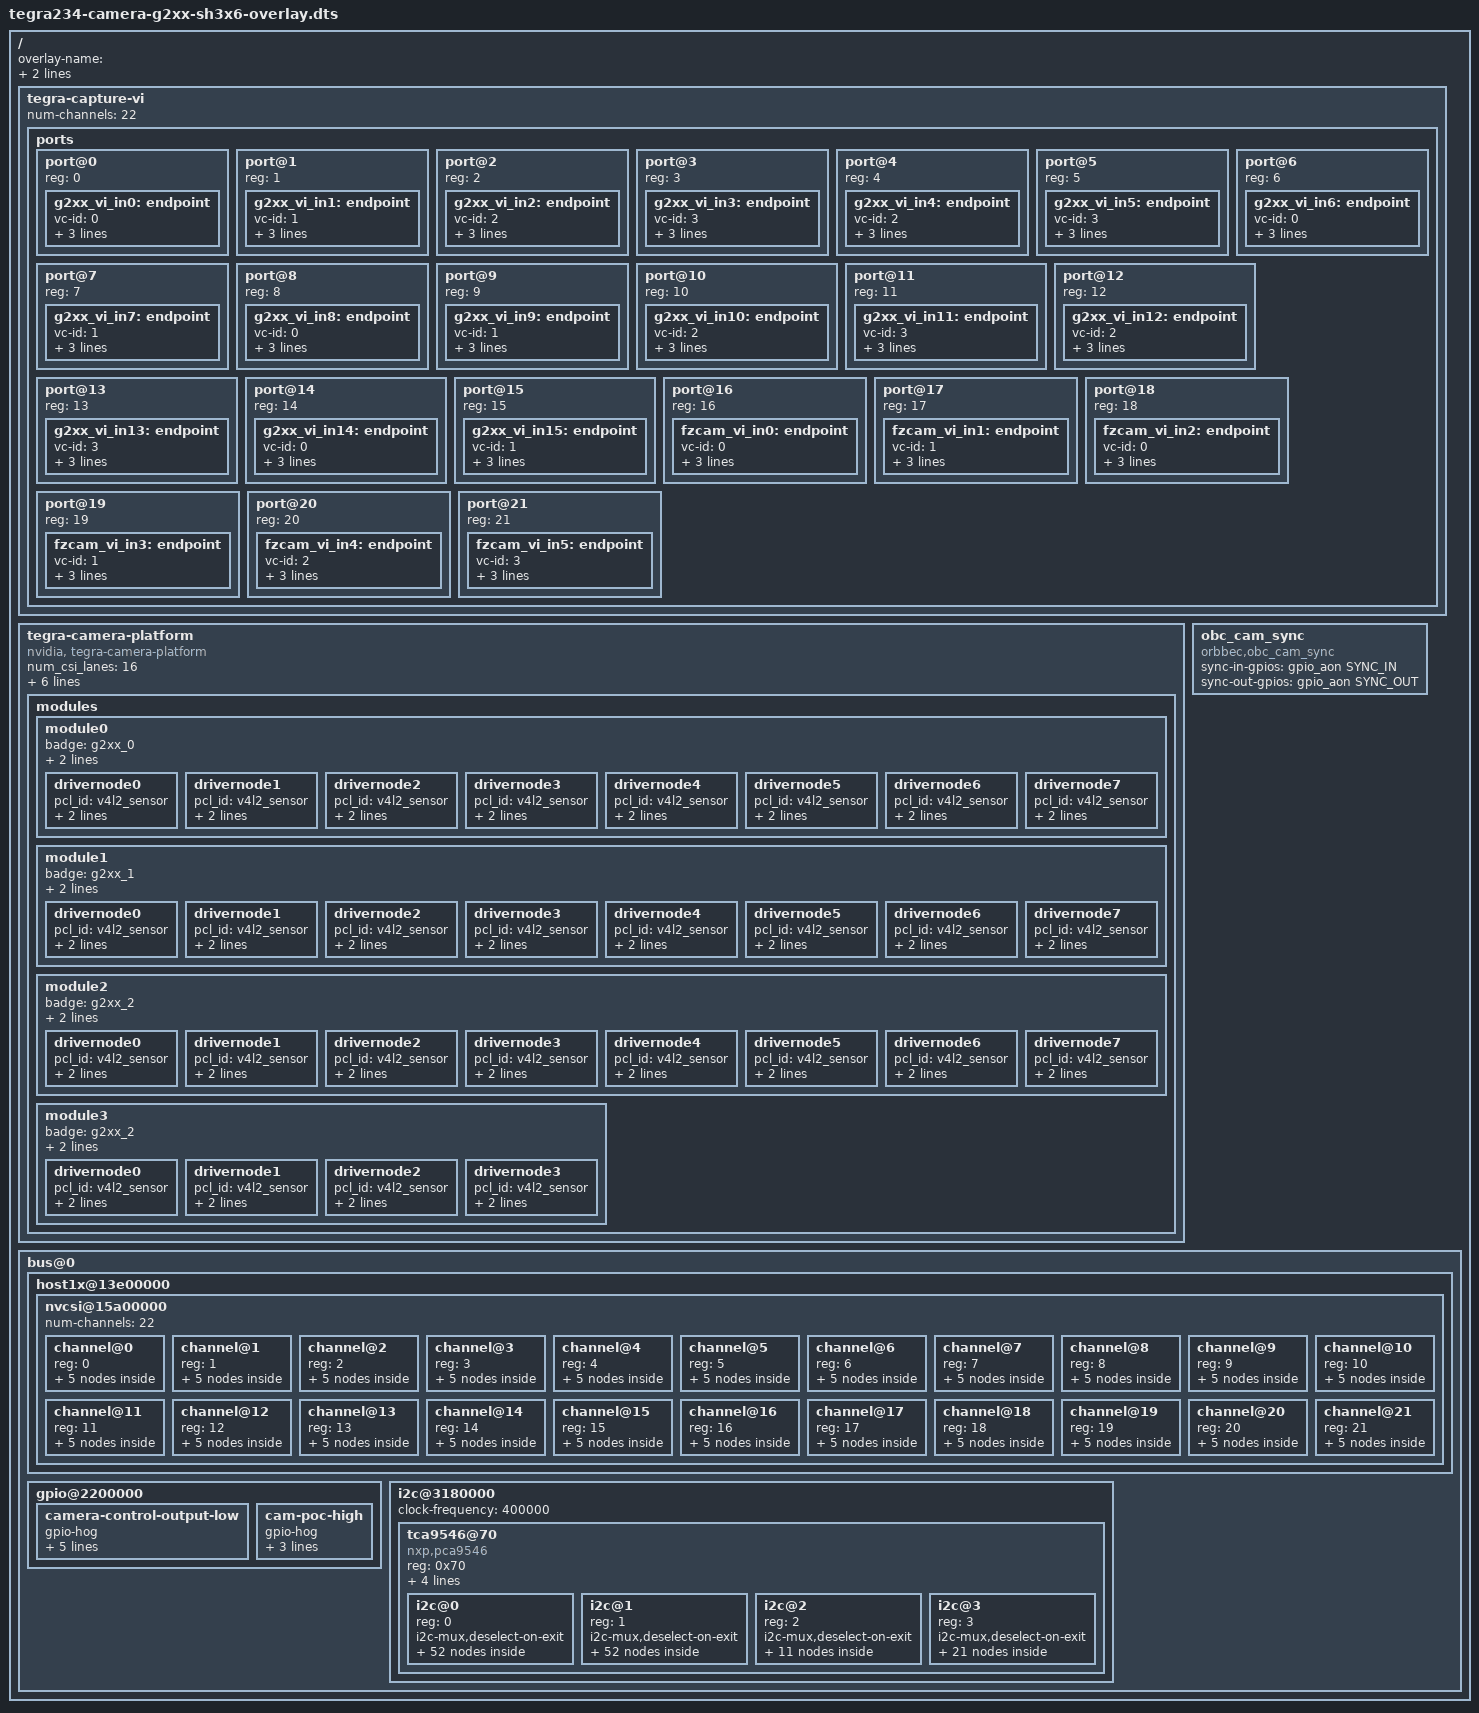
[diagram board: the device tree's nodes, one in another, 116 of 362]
// SPDX-License-Identifier: GPL-2.0-only
// SPDX-FileCopyrightText: Copyright (c) 2024-2024, ORBBEC CORPORATION.  All rights reserved.

/dts-v1/;
/plugin/;

#include <dt-bindings/clock/tegra234-clock.h>
#include <dt-bindings/gpio/tegra234-gpio.h>
#include <dt-bindings/tegra234-p3737-0000+p3701-0000.h>
#include <dt-bindings/pinctrl/pinctrl-tegra.h>

#define CAM1_PWDN	TEGRA234_MAIN_GPIO(H, 6)
#define CAM2_PWDN	TEGRA234_MAIN_GPIO(H, 3)
#define CAM3_PWDN	TEGRA234_MAIN_GPIO(AC, 0)
#define CAM4_PWDN	TEGRA234_MAIN_GPIO(AC, 1)

#define ISX031_POC	TEGRA234_MAIN_GPIO(AC, 4)
#define D457_POC	TEGRA234_MAIN_GPIO(AC, 7)

#define SYNC_OUT   TEGRA234_AON_GPIO(CC, 2)	//(CC, 2)
#define SYNC_IN    TEGRA234_AON_GPIO(BB, 0) //(BB, 0)
//#define SYNC_IN    TEGRA234_AON_GPIO(AA, 4) //(AA, 4)   // MAX3_CSI_SYNC

#define PPS_TRIGGER  TEGRA234_AON_GPIO(BB, 2)//(BB, 2)

#define CAMERA_I2C_MUX_BUS(x) (0x1E + x)

/* camera control gpio definitions */
/ {
	overlay-name = "Jetson Sensing Camera G335Lg And SH3 x6";
    jetson-header-name = "Jetson AGX CSI Connector";
    compatible = JETSON_COMPATIBLE;
	
	fragment@0 {
		target-path = "/";
		__overlay__ {
			tegra-capture-vi {
				num-channels = <22>;
				ports {
					status = "okay";
					#address-cells = <1>;
					#size-cells = <0>;
					port@0 {
						reg = <0>;
						status = "okay";
						g2xx_vi_in0: endpoint {
							status = "okay";
							vc-id = <0>;
							port-index = <4>; //0
							bus-width = <4>;
							remote-endpoint = <&g2xx_csi_out0>;
						};
					};
					port@1 {
						reg = <1>;
						status = "okay";
						g2xx_vi_in1: endpoint {
							status = "okay";
							vc-id = <1>;
							port-index = <4>; //0
							bus-width = <4>;
							remote-endpoint = <&g2xx_csi_out1>;
						};
					};
					port@2 {
						reg = <2>;
						status = "okay";
						g2xx_vi_in2: endpoint {
							status = "okay";
							vc-id = <2>;
							port-index = <4>; //0
							bus-width = <4>;
							remote-endpoint = <&g2xx_csi_out2>;
						};
					};
					port@3 {
						reg = <3>;
						status = "okay";
						g2xx_vi_in3: endpoint {
							status = "okay";
							vc-id = <3>;
							port-index = <4>; //0
							bus-width = <4>;
							remote-endpoint = <&g2xx_csi_out3>;
						};
					};

					port@4 {
						reg = <4>;
						status = "okay";
						g2xx_vi_in4: endpoint {
							status = "okay";
							vc-id = <2>;
							port-index = <4>; //1
							bus-width = <4>;
							remote-endpoint = <&g2xx_csi_out4>;
						};
					};
					port@5 {
						reg = <5>;
						status = "okay";
						g2xx_vi_in5: endpoint {
							status = "okay";
							vc-id = <3>;
							port-index = <4>; //1
							bus-width = <4>;
							remote-endpoint = <&g2xx_csi_out5>;
						};
					};
					port@6 {
						reg = <6>;
						status = "okay";
						g2xx_vi_in6: endpoint {
							status = "okay";
							vc-id = <0>;
							port-index = <4>; //1
							bus-width = <4>;
							remote-endpoint = <&g2xx_csi_out6>;
						};
					};
					port@7 {
						reg = <7>;
						status = "okay";
						g2xx_vi_in7: endpoint {
							status = "okay";
							vc-id = <1>;
							port-index = <4>; //1
							bus-width = <4>;
							remote-endpoint = <&g2xx_csi_out7>;
						};
					};

					port@8 {
						reg = <8>;
						status = "okay";
						g2xx_vi_in8: endpoint {
							status = "okay";
							vc-id = <0>;
							port-index = <2>; //2
							bus-width = <4>;
							remote-endpoint = <&g2xx_csi_out8>;
						};
					};
					port@9 {
						reg = <9>;
						status = "okay";
						g2xx_vi_in9: endpoint {
							status = "okay";
							vc-id = <1>;
							port-index = <2>; //2
							bus-width = <4>;
							remote-endpoint = <&g2xx_csi_out9>;
						};
					};
					port@10 {
						reg = <10>;
						status = "okay";
						g2xx_vi_in10: endpoint {
							status = "okay";
							vc-id = <2>;
							port-index = <2>; //2
							bus-width = <4>;
							remote-endpoint = <&g2xx_csi_out10>;
						};
					};
					port@11 {
						reg = <11>;
						status = "okay";
						g2xx_vi_in11: endpoint {
							status = "okay";
							vc-id = <3>;
							port-index = <2>; //2
							bus-width = <4>;
							remote-endpoint = <&g2xx_csi_out11>;
						};
					};

					port@12 {
						reg = <12>;
						status = "okay";
						g2xx_vi_in12: endpoint {
							status = "okay";
							vc-id = <2>;
							port-index = <2>; //3
							bus-width = <4>;
							remote-endpoint = <&g2xx_csi_out12>;
						};
					};
					port@13 {
						reg = <13>;
						status = "okay";
						g2xx_vi_in13: endpoint {
							status = "okay";
							vc-id = <3>;
							port-index = <2>; //3
							bus-width = <4>;
							remote-endpoint = <&g2xx_csi_out13>;
						};
					};
					port@14 {
						reg = <14>;
						status = "okay";
						g2xx_vi_in14: endpoint {
							status = "okay";
							vc-id = <0>;
							port-index = <2>; //3
							bus-width = <4>;
							remote-endpoint = <&g2xx_csi_out14>;
						};
					};
					port@15 {
						reg = <15>;
						status = "okay";
						g2xx_vi_in15: endpoint {
							status = "okay";
							vc-id = <1>;
							port-index = <2>; //3
							bus-width = <4>;
							remote-endpoint = <&g2xx_csi_out15>;
						};
					};
                    
                    //isx031
					port@16 {
						reg = <16>;
						status = "okay";
						fzcam_vi_in0: endpoint {
							status = "okay";
							vc-id = <0>;
							port-index = <0>; 
							bus-width = <4>;
							remote-endpoint = <&fzcam_csi_out0>;
						};
					};
					port@17 {
						reg = <17>;
						status = "okay";
						fzcam_vi_in1: endpoint {
							status = "okay";
							vc-id = <1>;
							port-index = <0>; 
							bus-width = <4>;
							remote-endpoint = <&fzcam_csi_out1>;
						};
					};
					
                    port@18 {
						reg = <18>;
						status = "okay";
						fzcam_vi_in2: endpoint {
							status = "okay";
							vc-id = <0>;
							port-index = <5>; //2
							bus-width = <4>;
							remote-endpoint = <&fzcam_csi_out2>;
						};
					};
					port@19 {
						reg = <19>;
						status = "okay";
						fzcam_vi_in3: endpoint {
							status = "okay";
							vc-id = <1>;
							port-index = <5>; //2
							bus-width = <4>;
							remote-endpoint = <&fzcam_csi_out3>;
						};
					};
					port@20 {
						reg = <20>;
						status = "okay";
						fzcam_vi_in4: endpoint {
							status = "okay";
							vc-id = <2>;
							port-index = <5>; 
							bus-width = <4>;
							remote-endpoint = <&fzcam_csi_out4>;
						};
					};
					port@21 {
						reg = <21>;
						status = "okay";
						fzcam_vi_in5: endpoint {
							status = "okay";
							vc-id = <3>;
							port-index = <5>; //3
							bus-width = <4>;
							remote-endpoint = <&fzcam_csi_out5>;
						};
					};
				};
			};
			tegra-camera-platform {
				compatible = "nvidia, tegra-camera-platform";

				num_csi_lanes = <16>;
				max_lane_speed = <4000000>;
				min_bits_per_pixel = <10>;
				vi_peak_byte_per_pixel = <2>;
				vi_bw_margin_pct = <25>;
				isp_peak_byte_per_pixel = <5>;
				isp_bw_margin_pct = <25>;

				modules {
					status = "okay";
					module0 {
						status = "okay";
						badge = "g2xx_0";
						position = "bottomleft";
						orientation = "1";
						drivernode0 {
							status = "okay";
							/* Declare PCL support driver (classically known as guid)  */
							pcl_id = "v4l2_sensor";
							/* Declare the device-tree hierarchy to driver instance */
							sysfs-device-tree = "/sys/firmware/devicetree/base/bus@0/i2c@3180000/tca9546@70/i2c@2/g2m0@66";
						};

						drivernode1 {
							status = "okay";
							/* Declare PCL support driver (classically known as guid)  */
							pcl_id = "v4l2_sensor";
							/* Declare the device-tree hierarchy to driver instance */
							sysfs-device-tree = "/sys/firmware/devicetree/base/bus@0/i2c@3180000/tca9546@70/i2c@2/g2m1@67";
						};

						drivernode2 {
							status = "okay";
							/* Declare PCL support driver (classically known as guid)  */
							pcl_id = "v4l2_sensor";
							/* Declare the device-tree hierarchy to driver instance */
							sysfs-device-tree = "/sys/firmware/devicetree/base/bus@0/i2c@3180000/tca9546@70/i2c@2/g2m2@68";
						};

						drivernode3 {
							status = "okay";
							/* Declare PCL support driver (classically known as guid)  */
							pcl_id = "v4l2_sensor";
							/* Declare the device-tree hierarchy to driver instance */
							sysfs-device-tree = "/sys/firmware/devicetree/base/bus@0/i2c@3180000/tca9546@70/i2c@0/g2m3@69";
						};

						drivernode4 {
							status = "okay";
							/* Declare PCL support driver (classically known as guid)  */
							pcl_id = "v4l2_sensor";
							/* Declare the device-tree hierarchy to driver instance */
							sysfs-device-tree = "/sys/firmware/devicetree/base/bus@0/i2c@3180000/tca9546@70/i2c@0/g2m0@6A";
						};

						drivernode5 {
							status = "okay";
							/* Declare PCL support driver (classically known as guid)  */
							pcl_id = "v4l2_sensor";
							/* Declare the device-tree hierarchy to driver instance */
							sysfs-device-tree = "/sys/firmware/devicetree/base/bus@0/i2c@3180000/tca9546@70/i2c@0/g2m1@6B";
						};

						drivernode6 {
							status = "okay";
							/* Declare PCL support driver (classically known as guid)  */
							pcl_id = "v4l2_sensor";
							/* Declare the device-tree hierarchy to driver instance */
							sysfs-device-tree = "/sys/firmware/devicetree/base/bus@0/i2c@3180000/tca9546@70/i2c@0/g2m2@6C";
						};

						drivernode7 {
							status = "okay";
							/* Declare PCL support driver (classically known as guid)  */
							pcl_id = "v4l2_sensor";
							/* Declare the device-tree hierarchy to driver instance */
							sysfs-device-tree = "/sys/firmware/devicetree/base/bus@0/i2c@3180000/tca9546@70/i2c@0/g2m3@6D";
						};
					};

					module1 {
						status = "okay";
						badge = "g2xx_1";
						position = "bottomright";
						orientation = "1";

						drivernode0 {
							status = "okay";
							/* Declare PCL support driver (classically known as guid)  */
							pcl_id = "v4l2_sensor";
							sysfs-device-tree = "/sys/firmware/devicetree/base/bus@0/i2c@3180000/tca9546@70/i2c@1/g2m0@66";
						};

						drivernode1 {
							status = "okay";
							/* Declare PCL support driver (classically known as guid)  */
							pcl_id = "v4l2_sensor";
							/* Declare the device-tree hierarchy to driver instance */
							sysfs-device-tree = "/sys/firmware/devicetree/base/bus@0/i2c@3180000/tca9546@70/i2c@1/g2m1@67";
						};

						drivernode2 {
							status = "okay";
							/* Declare PCL support driver (classically known as guid)  */
							pcl_id = "v4l2_sensor";
							/* Declare the device-tree hierarchy to driver instance */
							sysfs-device-tree = "/sys/firmware/devicetree/base/bus@0/i2c@3180000/tca9546@70/i2c@1/g2m2@68";
						};

						drivernode3 {
							status = "okay";
							/* Declare PCL support driver (classically known as guid)  */
							pcl_id = "v4l2_sensor";
							/* Declare the device-tree hierarchy to driver instance */
							sysfs-device-tree = "/sys/firmware/devicetree/base/bus@0/i2c@3180000/tca9546@70/i2c@1/g2m3@69";
						};

						drivernode4 {
							status = "okay";
								/* Declare PCL support driver (classically known as guid)  */
							pcl_id = "v4l2_sensor";
							/* Declare the device-tree hierarchy to driver instance */
							sysfs-device-tree = "/sys/firmware/devicetree/base/bus@0/i2c@3180000/tca9546@70/i2c@1/g2m0@6A";
						};

						drivernode5 {
							status = "okay";
							/* Declare PCL support driver (classically known as guid)  */
							pcl_id = "v4l2_sensor";
							/* Declare the device-tree hierarchy to driver instance */
							sysfs-device-tree = "/sys/firmware/devicetree/base/bus@0/i2c@3180000/tca9546@70/i2c@1/g2m1@6B";
						};

						drivernode6 {
							status = "okay";
							/* Declare PCL support driver (classically known as guid)  */
							pcl_id = "v4l2_sensor";
							/* Declare the device-tree hierarchy to driver instance */
							sysfs-device-tree = "/sys/firmware/devicetree/base/bus@0/i2c@3180000/tca9546@70/i2c@1/g2m2@6C";
						};

						drivernode7 {
							status = "okay";
							/* Declare PCL support driver (classically known as guid)  */
							pcl_id = "v4l2_sensor";
							/* Declare the device-tree hierarchy to driver instance */
							sysfs-device-tree = "/sys/firmware/devicetree/base/bus@0/i2c@3180000/tca9546@70/i2c@1/g2m3@6D";
						};
					};

					module2 {
						status = "okay";
						badge = "g2xx_2";
						position = "centerleft";
						orientation = "1";

						drivernode0 {
							status = "okay";
							/* Declare PCL support driver (classically known as guid)  */
							pcl_id = "v4l2_sensor";
							sysfs-device-tree = "/sys/firmware/devicetree/base/bus@0/i2c@3180000/tca9546@70/i2c@0/g2m0@66";
						};

						drivernode1 {
							status = "okay";
							/* Declare PCL support driver (classically known as guid)  */
							pcl_id = "v4l2_sensor";
							/* Declare the device-tree hierarchy to driver instance */
							sysfs-device-tree = "/sys/firmware/devicetree/base/bus@0/i2c@3180000/tca9546@70/i2c@0/g2m1@67";
						};

						drivernode2 {
							status = "okay";
							/* Declare PCL support driver (classically known as guid)  */
							pcl_id = "v4l2_sensor";
							/* Declare the device-tree hierarchy to driver instance */
							sysfs-device-tree = "/sys/firmware/devicetree/base/bus@0/i2c@3180000/tca9546@70/i2c@0/g2m2@68";
						};

						drivernode3 {
							status = "okay";
							/* Declare PCL support driver (classically known as guid)  */
							pcl_id = "v4l2_sensor";
							/* Declare the device-tree hierarchy to driver instance */
							sysfs-device-tree = "/sys/firmware/devicetree/base/bus@0/i2c@3180000/tca9546@70/i2c@0/g2m3@69";
						};

						drivernode4 {
							status = "okay";
								/* Declare PCL support driver (classically known as guid)  */
							pcl_id = "v4l2_sensor";
							/* Declare the device-tree hierarchy to driver instance */
							sysfs-device-tree = "/sys/firmware/devicetree/base/bus@0/i2c@3180000/tca9546@70/i2c@0/g2m0@6A";
						};

						drivernode5 {
							status = "okay";
							/* Declare PCL support driver (classically known as guid)  */
							pcl_id = "v4l2_sensor";
							/* Declare the device-tree hierarchy to driver instance */
							sysfs-device-tree = "/sys/firmware/devicetree/base/bus@0/i2c@3180000/tca9546@70/i2c@0/g2m1@6B";
						};

						drivernode6 {
							status = "okay";
							/* Declare PCL support driver (classically known as guid)  */
							pcl_id = "v4l2_sensor";
							/* Declare the device-tree hierarchy to driver instance */
							sysfs-device-tree = "/sys/firmware/devicetree/base/bus@0/i2c@3180000/tca9546@70/i2c@0/g2m2@6C";
						};

						drivernode7 {
							status = "okay";
							/* Declare PCL support driver (classically known as guid)  */
							pcl_id = "v4l2_sensor";
							/* Declare the device-tree hierarchy to driver instance */
							sysfs-device-tree = "/sys/firmware/devicetree/base/bus@0/i2c@3180000/tca9546@70/i2c@0/g2m3@6D";
						};
					};
                    module3 {
						status = "okay";
						badge = "g2xx_2";
						position = "centerright";
						orientation = "1";

						drivernode0 {
							status = "okay";
							/* Declare PCL support driver (classically known as guid)  */
							pcl_id = "v4l2_sensor";
							sysfs-device-tree = "/sys/firmware/devicetree/base/bus@0/i2c@3180000/tca9546@70/i2c@3/g2m0@66";
						};

						drivernode1 {
							status = "okay";
							/* Declare PCL support driver (classically known as guid)  */
							pcl_id = "v4l2_sensor";
							/* Declare the device-tree hierarchy to driver instance */
							sysfs-device-tree = "/sys/firmware/devicetree/base/bus@0/i2c@3180000/tca9546@70/i2c@3/g2m1@67";
						};

						drivernode2 {
							status = "okay";
							/* Declare PCL support driver (classically known as guid)  */
							pcl_id = "v4l2_sensor";
							/* Declare the device-tree hierarchy to driver instance */
							sysfs-device-tree = "/sys/firmware/devicetree/base/bus@0/i2c@3180000/tca9546@70/i2c@3/g2m2@68";
						};

						drivernode3 {
							status = "okay";
							/* Declare PCL support driver (classically known as guid)  */
							pcl_id = "v4l2_sensor";
							/* Declare the device-tree hierarchy to driver instance */
							sysfs-device-tree = "/sys/firmware/devicetree/base/bus@0/i2c@3180000/tca9546@70/i2c@3/g2m3@69";
						};
					};
				};
			};

			obc_cam_sync {
				compatible = "orbbec,obc_cam_sync";
				sync-in-gpios = <&gpio_aon SYNC_IN GPIO_ACTIVE_HIGH>;
				sync-out-gpios = <&gpio_aon SYNC_OUT GPIO_ACTIVE_HIGH>;  //Use hrtimer to generate trigger signals
			};

			bus@0 {
				host1x@13e00000 {
					nvcsi@15a00000 {
						#address-cells = <1>;
						#size-cells = <0>;

						num-channels = <22>;

						channel@0 {
							reg = <0>;
							status = "okay";
							ports {
								status = "okay";
								#address-cells = <1>;
								#size-cells = <0>;
								port@0 {
									reg = <0>;
									status = "okay";
									g2xx_csi_in0: endpoint@0 {
										status = "okay";
										port-index = <4>; //0
										bus-width = <4>;
										remote-endpoint = <&g2m0_0_out>;
									};
								};
								port@1 {
									reg = <1>;
									status = "okay";
									g2xx_csi_out0: endpoint@1 {
										status = "okay";
										remote-endpoint = <&g2xx_vi_in0>;
									};
								};
							};
						};
						channel@1 {
							reg = <1>;
							status = "okay";
							ports {
								status = "okay";
								#address-cells = <1>;
								#size-cells = <0>;
								port@0 {
									reg = <0>;
									status = "okay";
									g2xx_csi_in1: endpoint@2 {
										status = "okay";
										port-index = <4>; //0
										bus-width = <4>;
										remote-endpoint = <&g2m0_1_out>;
									};
								};
								port@1 {
									reg = <1>;
									status = "okay";
									g2xx_csi_out1: endpoint@3 {
										status = "okay";
										remote-endpoint = <&g2xx_vi_in1>;
									};
								};
							};
						};
						channel@2 {
							reg = <2>;
							status = "okay";
							ports {
								status = "okay";
								#address-cells = <1>;
								#size-cells = <0>;
								port@0 {
									reg = <0>;
									status = "okay";
									g2xx_csi_in2: endpoint@4 {
										status = "okay";
										port-index = <4>; //0
										bus-width = <4>;
										remote-endpoint = <&g2m0_2_out>;
									};
								};
								port@1 {
									reg = <1>;
									status = "okay";
									g2xx_csi_out2: endpoint@5 {
										status = "okay";
										remote-endpoint = <&g2xx_vi_in2>;
									};
								};
							};
						};
						channel@3 {
							reg = <3>;
							status = "okay";
							ports {
								status = "okay";
								#address-cells = <1>;
								#size-cells = <0>;
								port@0 {
									reg = <0>;
									status = "okay";
									g2xx_csi_in3: endpoint@6 {
										status = "okay";
										port-index = <4>; //0
										bus-width = <4>;
										remote-endpoint = <&g2m0_3_out>;
									};
								};
								port@1 {
									reg = <1>;
									status = "okay";
									g2xx_csi_out3: endpoint@7 {
										status = "okay";
										remote-endpoint = <&g2xx_vi_in3>;
									};
								};
							};
						};

						channel@4 {
							reg = <4>;
							status = "okay";
							ports {
								status = "okay";
								#address-cells = <1>;
								#size-cells = <0>;
								port@0 {
									reg = <0>;
									status = "okay";
									g2xx_csi_in4: endpoint@8 {
										status = "okay";
										port-index = <4>; //1
										bus-width = <4>;
										remote-endpoint = <&g2m1_0_out>;
									};
								};
								port@1 {
									reg = <1>;
									status = "okay";
									g2xx_csi_out4: endpoint@9 {
										status = "okay";
										remote-endpoint = <&g2xx_vi_in4>;
									};
								};
							};
						};
						channel@5 {
							reg = <5>;
							status = "okay";
							ports {
								status = "okay";
								#address-cells = <1>;
								#size-cells = <0>;
								port@0 {
									reg = <0>;
									status = "okay";
									g2xx_csi_in5: endpoint@10 {
										status = "okay";
										port-index = <4>; //1
										bus-width = <4>;
										remote-endpoint = <&g2m1_1_out>;
									};
								};
								port@1 {
									reg = <1>;
									status = "okay";
									g2xx_csi_out5: endpoint@11 {
										status = "okay";
										remote-endpoint = <&g2xx_vi_in5>;
									};
								};
							};
						};
						channel@6 {
							reg = <6>;
							status = "okay";
							ports {
								status = "okay";
								#address-cells = <1>;
								#size-cells = <0>;
								port@0 {
									reg = <0>;
									status = "okay";
									g2xx_csi_in6: endpoint@12 {
										status = "okay";
										port-index = <4>; //1
										bus-width = <4>;
										remote-endpoint = <&g2m1_2_out>;
									};
								};
								port@1 {
									reg = <1>;
									status = "okay";
									g2xx_csi_out6: endpoint@13 {
										status = "okay";
										remote-endpoint = <&g2xx_vi_in6>;
									};
								};
							};
						};
						channel@7 {
							reg = <7>;
							status = "okay";
							ports {
								status = "okay";
								#address-cells = <1>;
								#size-cells = <0>;
								port@0 {
									reg = <0>;
									status = "okay";
									g2xx_csi_in7: endpoint@14 {
										status = "okay";
										port-index = <4>; //1
										bus-width = <4>;
										remote-endpoint = <&g2m1_3_out>;
									};
								};
								port@1 {
									reg = <1>;
									status = "okay";
									g2xx_csi_out7: endpoint@15 {
										status = "okay";
										remote-endpoint = <&g2xx_vi_in7>;
									};
								};
							};
						};

						channel@8 {
							reg = <8>;
							status = "okay";
							ports {
								status = "okay";
								#address-cells = <1>;
								#size-cells = <0>;
								port@0 {
									reg = <0>;
									status = "okay";
									g2xx_csi_in8: endpoint@16 {
										status = "okay";
										port-index = <2>; //2
										bus-width = <4>;
										remote-endpoint = <&g2m2_0_out>;
									};
								};
								port@1 {
									reg = <1>;
									status = "okay";
									g2xx_csi_out8: endpoint@17 {
										status = "okay";
										remote-endpoint = <&g2xx_vi_in8>;
									};
								};
							};
						};
						channel@9 {
							reg = <9>;
							status = "okay";
							ports {
								status = "okay";
								#address-cells = <1>;
								#size-cells = <0>;
								port@0 {
									reg = <0>;
									status = "okay";
									g2xx_csi_in9: endpoint@18 {
										status = "okay";
										port-index = <2>; //2
										bus-width = <4>;
										remote-endpoint = <&g2m2_1_out>;
									};
								};
								port@1 {
									reg = <1>;
									status = "okay";
									g2xx_csi_out9: endpoint@19 {
										status = "okay";
										remote-endpoint = <&g2xx_vi_in9>;
									};
								};
							};
						};
						channel@10 {
							reg = <10>;
							status = "okay";
							ports {
								status = "okay";
								#address-cells = <1>;
								#size-cells = <0>;
								port@0 {
									reg = <0>;
									status = "okay";
									g2xx_csi_in10: endpoint@20 {
										status = "okay";
										port-index = <2>; //2
										bus-width = <4>;
										remote-endpoint = <&g2m2_2_out>;
									};
								};
								port@1 {
									reg = <1>;
									status = "okay";
									g2xx_csi_out10: endpoint@21 {
										status = "okay";
										remote-endpoint = <&g2xx_vi_in10>;
									};
								};
							};
						};
						channel@11 {
							reg = <11>;
							status = "okay";
							ports {
								status = "okay";
								#address-cells = <1>;
								#size-cells = <0>;
								port@0 {
									reg = <0>;
									status = "okay";
									g2xx_csi_in11: endpoint@22 {
										status = "okay";
										port-index = <2>; //2
										bus-width = <4>;
										remote-endpoint = <&g2m2_3_out>;
									};
								};
								port@1 {
									reg = <1>;
									status = "okay";
									g2xx_csi_out11: endpoint@23 {
										status = "okay";
										remote-endpoint = <&g2xx_vi_in11>;
									};
								};
							};
						};

						channel@12 {
							reg = <12>;
							status = "okay";
							ports {
								status = "okay";
								#address-cells = <1>;
								#size-cells = <0>;
								port@0 {
									reg = <0>;
									status = "okay";
									g2xx_csi_in12: endpoint@24 {
										status = "okay";
										port-index = <2>; //3
										bus-width = <4>;
										remote-endpoint = <&g2m3_0_out>;
									};
								};
								port@1 {
									reg = <1>;
									status = "okay";
									g2xx_csi_out12: endpoint@25 {
										status = "okay";
										remote-endpoint = <&g2xx_vi_in12>;
									};
								};
							};
						};
						channel@13 {
							reg = <13>;
							status = "okay";
							ports {
								status = "okay";
								#address-cells = <1>;
								#size-cells = <0>;
								port@0 {
									reg = <0>;
									status = "okay";
									g2xx_csi_in13: endpoint@26 {
										status = "okay";
										port-index = <2>; //3
										bus-width = <4>;
										remote-endpoint = <&g2m3_1_out>;
									};
								};
								port@1 {
									reg = <1>;
									status = "okay";
									g2xx_csi_out13: endpoint@27 {
										status = "okay";
										remote-endpoint = <&g2xx_vi_in13>;
									};
								};
							};
						};
						channel@14 {
							reg = <14>;
							status = "okay";
							ports {
								status = "okay";
								#address-cells = <1>;
								#size-cells = <0>;
								port@0 {
									reg = <0>;
									status = "okay";
									g2xx_csi_in14: endpoint@28 {
										status = "okay";
										port-index = <2>; //3
										bus-width = <4>;
										remote-endpoint = <&g2m3_2_out>;
									};
								};
								port@1 {
									reg = <1>;
									status = "okay";
									g2xx_csi_out14: endpoint@29 {
										status = "okay";
										remote-endpoint = <&g2xx_vi_in14>;
									};
								};
							};
						};
						channel@15 {
							reg = <15>;
							status = "okay";
							ports {
								status = "okay";
								#address-cells = <1>;
								#size-cells = <0>;
								port@0 {
									reg = <0>;
									status = "okay";
									g2xx_csi_in15: endpoint@30 {
										status = "okay";
										port-index = <2>; //3
										bus-width = <4>;
										remote-endpoint = <&g2m3_3_out>;
									};
								};
								port@1 {
									reg = <1>;
									status = "okay";
									g2xx_csi_out15: endpoint@31 {
										status = "okay";
										remote-endpoint = <&g2xx_vi_in15>;
									};
								};
							};
						};

                        //isx031
						channel@16 {
							reg = <16>;
							status = "okay";
							ports {
								status = "okay";
								#address-cells = <1>;
								#size-cells = <0>;
								port@0 {
									reg = <0>;
									status = "okay";
									fzcam_csi_in0: endpoint@32 {
										status = "okay";
										port-index = <0>; 
										bus-width = <4>;
										remote-endpoint = <&fzcam_fzcam_out0>;
									};
								};
								port@1 {
									reg = <1>;
									status = "okay";
									fzcam_csi_out0: endpoint@33 {
										status = "okay";
										remote-endpoint = <&fzcam_vi_in0>;
									};
								};
							};
						};
						channel@17 {
							reg = <17>;
							status = "okay";
							ports {
								status = "okay";
								#address-cells = <1>;
								#size-cells = <0>;
								port@0 {
									reg = <0>;
									status = "okay";
									fzcam_csi_in1: endpoint@34 {
										status = "okay";
										port-index = <0>; 
										bus-width = <4>;
										remote-endpoint = <&fzcam_fzcam_out1>;
									};
								};
								port@1 {
									reg = <1>;
									status = "okay";
									fzcam_csi_out1: endpoint@35 {
										status = "okay";
										remote-endpoint = <&fzcam_vi_in1>;
									};
								};
							};
						};
                        
						channel@18 {
							reg = <18>;
							status = "okay";
							ports {
								status = "okay";
								#address-cells = <1>;
								#size-cells = <0>;
								port@0 {
									reg = <0>;
									status = "okay";
									fzcam_csi_in2: endpoint@36 {
										status = "okay";
										port-index = <6>; 
										bus-width = <4>;
										remote-endpoint = <&fzcam_fzcam_out2>;
									};
								};
								port@1 {
									reg = <1>;
									status = "okay";
									fzcam_csi_out2: endpoint@37 {
										status = "okay";
										remote-endpoint = <&fzcam_vi_in2>;
									};
								};
							};
						};
						channel@19 {
							reg = <19>;
							status = "okay";
							ports {
								status = "okay";
								#address-cells = <1>;
								#size-cells = <0>;
								port@0 {
									reg = <0>;
									status = "okay";
									fzcam_csi_in3: endpoint@38 {
										status = "okay";
										port-index = <6>; 
										bus-width = <4>;
										remote-endpoint = <&fzcam_fzcam_out3>;
									};
								};
								port@1 {
									reg = <1>;
									status = "okay";
									fzcam_csi_out3: endpoint@39 {
										status = "okay";
										remote-endpoint = <&fzcam_vi_in3>;
									};
								};
							};
						};
						channel@20 {
							reg = <20>;
							status = "okay";
							ports {
								status = "okay";
								#address-cells = <1>;
								#size-cells = <0>;
								port@0 {
									reg = <0>;
									status = "okay";
									fzcam_csi_in4: endpoint@40 {
										status = "okay";
										port-index = <6>; 
										bus-width = <4>;
										remote-endpoint = <&fzcam_fzcam_out4>;
									};
								};
								port@1 {
									reg = <1>;
									status = "okay";
									fzcam_csi_out4: endpoint@41 {
										status = "okay";
										remote-endpoint = <&fzcam_vi_in4>;
									};
								};
							};
						};
						channel@21 {
							reg = <21>;
							status = "okay";
							ports {
								status = "okay";
								#address-cells = <1>;
								#size-cells = <0>;
								port@0 {
									reg = <0>;
									status = "okay";
									fzcam_csi_in5: endpoint@42 {
										status = "okay";
										port-index = <6>; 
										bus-width = <4>;
										remote-endpoint = <&fzcam_fzcam_out5>;
									};
								};
								port@1 {
									reg = <1>;
									status = "okay";
									fzcam_csi_out5: endpoint@43 {
										status = "okay";
										remote-endpoint = <&fzcam_vi_in5>;
									};
								};
							};
						};
					};
				};

				gpio@2200000 {
					// cam-pwdn-high {
					// 	gpio-hog;
					// 	output-high;
					// 	gpios = <CAM1_PWDN 0 CAM2_PWDN 0
					// 		 CAM3_PWDN 0 CAM4_PWDN 0>;
					// 	// gpios = <CAM1_PWDN 0 CAM2_PWDN 0>;
					// 	label = "cam1-pwdn", "cam2-pwdn",
					// 		"cam3-pwdn", "cam4-pwdn";
					// 	// label = "cam1-pwdn", "cam2-pwdn";
					// };

                    
					camera-control-output-low {
						gpio-hog;
						output-low;
						gpios = <CAM1_PWDN 0 CAM2_PWDN 0
						    CAM3_PWDN 0 CAM4_PWDN 0>;
						label = "cam1-pwdn", "cam2-pwdn",
						    "cam3-pwdn", "cam4-pwdn";
					};
				    

					cam-poc-high {
						gpio-hog;
						output-high;
						gpios = <ISX031_POC 0 D457_POC 0>;
						label = "isx031-poc", "d457-poc";
					};
					// camera-control-output-high {
					// 	gpio-hog;
					// 	output-high;
					// 	gpios = <ISX031_POC 0 D457_POC 0>; 
					// 	label = "isx031-poc", "d457-poc";
					// };
				};

				i2c@3180000 {
					status = "okay";
					clock-frequency = <400000>;
					tca9546@70 {
						status = "okay";
						reg = <0x70>;
						compatible = "nxp,pca9546";
						#address-cells = <1>;
						#size-cells = <0>;
						skip_mux_detect = "yes";
						vcc-supply = <&vdd_1v8_ls>;
						/*vcc-pullup-supply = <&battery_reg>;*/
						force_bus_start = <CAMERA_I2C_MUX_BUS(0)>;
						vcc_lp = "vcc";

						i2c@0 {
							status = "okay";
							reg = <0>; // line 4 of the I2C switch
							i2c-mux,deselect-on-exit;
							#address-cells = <1>;
							#size-cells = <0>;

                            g2m1_3: g2m3@6D {
								status = "okay";
								def-addr = <0x66>;
								reg = <0x6D>;
								compatible = "orbbec,g2xx";
								use_sensor_mode_id = "true";
								vcc-supply = <&vdd_1v8_ls>;
								cam-type = "IR_R";
								orbbec_cam_num = <1>;
								nvidia,gmsl-ser-device = <&ser0_b>;
								nvidia,gmsl-dser-device = <&dser0>;
								pps-gpios = <&gpio_aon PPS_TRIGGER GPIO_ACTIVE_LOW>;
								ports {
									#address-cells = <1>;
									#size-cells = <0>;

									port@0 {
										reg = <0>;
										g2m1_3_out: endpoint {
											vc-id = <1>;
											port-index = <4>;
											bus-width = <4>;
											remote-endpoint = <&g2xx_csi_in7>;
										};
									};
								};
								mode0 {
									pixel_t = "grey_y8";
									num_lanes = "4";
									csi_pixel_bit_depth = "8";
									active_w = "1280";
									active_h = "720";
									tegra_sinterface = "serial_e";
									mclk_khz = "24000";
									pix_clk_hz = "750000000";
									serdes_pix_clk_hz = "750000000";
									discontinuous_clk = "no";
									dpcm_enable = "false";
									cil_settletime = "0";
									line_length = "1280";
									mclk_multiplier = "15.625";
									embedded_metadata_height = "1";
									vc_id = "1";
								};
								gmsl-link {
									src-csi-port = "b"; //a = depth + ir_l, b = rgb + ir_r
									dst-csi-port = "a";
									serdes-csi-link = "b";
									csi-mode = "1x4";
									st-vc = <3>;
									vc-id = <1>;
									num-lanes = <4>;
								};
							};
							g2m1_2: g2m2@6C {
								status = "okay";
								def-addr = <0x66>;
								reg = <0x6C>;
								compatible = "orbbec,g2xx";
								use_sensor_mode_id = "true";
								vcc-supply = <&vdd_1v8_ls>;
								cam-type = "IR_L";
								orbbec_cam_num = <1>;
								nvidia,gmsl-ser-device = <&ser0_b>;
								nvidia,gmsl-dser-device = <&dser0>;
								pps-gpios = <&gpio_aon PPS_TRIGGER GPIO_ACTIVE_LOW>;
								ports {
									#address-cells = <1>;
									#size-cells = <0>;

									port@0 {
										reg = <0>;
										g2m1_2_out: endpoint {
											vc-id = <0>;
											port-index = <4>;
											bus-width = <4>;
											remote-endpoint = <&g2xx_csi_in6>;
										};
									};
								};
								mode0 {
									pixel_t = "grey_y8";
									num_lanes = "4";
									csi_pixel_bit_depth = "8";
									active_w = "1280";
									active_h = "720";
									tegra_sinterface = "serial_e";
									mclk_khz = "24000";
									pix_clk_hz = "750000000";
									serdes_pix_clk_hz = "750000000";
									discontinuous_clk = "no";
									dpcm_enable = "false";
									cil_settletime = "0";
									line_length = "1280";
									mclk_multiplier = "15.625";
									embedded_metadata_height = "1";
									vc_id = "0";
								};
								gmsl-link {
									src-csi-port = "a"; //a = depth + ir_l, b = rgb + ir_r
									dst-csi-port = "a";
									serdes-csi-link = "b";
									csi-mode = "1x4";
									st-vc = <2>;
									vc-id = <0>;
									num-lanes = <4>;
								};
							};
							g2m1_1: g2m1@6B {
								status = "okay";
								def-addr = <0x66>;
								reg = <0x6B>;
								compatible = "orbbec,g2xx";
								use_sensor_mode_id = "true";
								vcc-supply = <&vdd_1v8_ls>;
								cam-type = "RGB";
								orbbec_cam_num = <1>;
								nvidia,gmsl-ser-device = <&ser0_b>;
								nvidia,gmsl-dser-device = <&dser0>;
								pps-gpios = <&gpio_aon PPS_TRIGGER GPIO_ACTIVE_LOW>;
								ports {
									#address-cells = <1>;
									#size-cells = <0>;

									port@0 {
										reg = <0>;
										g2m1_1_out: endpoint {
											vc-id = <3>;
											port-index = <4>;
											bus-width = <4>;
											remote-endpoint = <&g2xx_csi_in5>;
										};
									};
								};
								mode0 {
									pixel_t = "yuv_yvyu16";
									num_lanes = "4";
									csi_pixel_bit_depth = "16";
									active_w = "1280";
									active_h = "720";
									tegra_sinterface = "serial_e";
									mclk_khz = "24000";
									pix_clk_hz = "375000000";
									serdes_pix_clk_hz = "375000000";
									discontinuous_clk = "no";
									dpcm_enable = "false";
									cil_settletime = "0";
									line_length = "1280";
									mclk_multiplier = "15.625";
									embedded_metadata_height = "1";
									vc_id = "3";
								};
								gmsl-link {
									src-csi-port = "b"; //a = depth + ir_l, b = rgb + ir_r
									dst-csi-port = "a";
									serdes-csi-link = "b";
									csi-mode = "1x4";
									st-vc = <1>;
									vc-id = <3>;
									num-lanes = <4>;
								};
							};
							g2m1_0: g2m0@6A {
								status = "okay";
								def-addr = <0x66>;
								reg = <0x6A>;
								compatible = "orbbec,g2xx";
								use_sensor_mode_id = "true";
								vcc-supply = <&vdd_1v8_ls>;
								cam-type = "Depth";
								orbbec_cam_num = <1>;
								nvidia,gmsl-ser-device = <&ser0_b>;
								nvidia,gmsl-dser-device = <&dser0>;
								pps-gpios = <&gpio_aon PPS_TRIGGER GPIO_ACTIVE_LOW>;
								ports {
									#address-cells = <1>;
									#size-cells = <0>;

									port@0 {
										reg = <0>;
										g2m1_0_out: endpoint {
											vc-id = <2>;
											port-index = <4>;
											bus-width = <4>;
											remote-endpoint = <&g2xx_csi_in4>;
										};
									};
								};
								mode0 {
									pixel_t = "yuv_yvyu16";
									num_lanes = "4";
									csi_pixel_bit_depth = "16";
									active_w = "1280";
									active_h = "720";
									tegra_sinterface = "serial_e";
									mclk_khz = "24000";
									pix_clk_hz = "375000000";
									serdes_pix_clk_hz = "375000000";
									discontinuous_clk = "no";
									dpcm_enable = "false";
									cil_settletime = "0";
									line_length = "1280";
									mclk_multiplier = "15.625";
									embedded_metadata_height = "1";
									vc_id = "2";
								};
								gmsl-link {
									src-csi-port = "a"; //a = depth + ir_l, b = rgb + ir_r
									dst-csi-port = "a";
									serdes-csi-link = "b";
									csi-mode = "1x4";
									st-vc = <0>;
									vc-id = <2>;
									num-lanes = <4>;
								};
							};

							/* IR_R */
							g2m0_3: g2m3@69 {
								status = "okay";
								def-addr = <0x66>;
								reg = <0x69>;
								compatible = "orbbec,g2xx";
								use_sensor_mode_id = "true";
								vcc-supply = <&vdd_1v8_ls>;
								cam-type = "IR_R";
								orbbec_cam_num = <0>;
								nvidia,gmsl-ser-device = <&ser0_a>;
								nvidia,gmsl-dser-device = <&dser0>;
								pps-gpios = <&gpio_aon PPS_TRIGGER GPIO_ACTIVE_LOW>;
								ports {
									#address-cells = <1>;
									#size-cells = <0>;

									port@0 {
										reg = <0>;
										g2m0_3_out: endpoint {
											vc-id = <3>;
											port-index = <4>; //0
											bus-width = <4>;
											remote-endpoint = <&g2xx_csi_in3>;
										};
									};
								};
								mode0 {
									pixel_t = "grey_y8";
									num_lanes = "4";
									csi_pixel_bit_depth = "8";
									active_w = "1280";
									active_h = "720";
									tegra_sinterface = "serial_e";
									mclk_khz = "24000";
									pix_clk_hz = "750000000";
									serdes_pix_clk_hz = "750000000";
									discontinuous_clk = "no";
									dpcm_enable = "false";
									cil_settletime = "0";
									line_length = "1280";
									mclk_multiplier = "15.625";
									embedded_metadata_height = "1";
									vc_id = "3";
								};
								gmsl-link {
									src-csi-port = "b"; //a = depth + ir_l, b = rgb + ir_r
									dst-csi-port = "a";
									serdes-csi-link = "a";
									csi-mode = "1x4";
									st-vc = <3>;
									vc-id = <3>;
									num-lanes = <4>;
								};
							};
							/* IR_L */
							g2m0_2: g2m2@68 {
								status = "okay";
								def-addr = <0x66>;
								reg = <0x68>;
								compatible = "orbbec,g2xx";
								use_sensor_mode_id = "true";
								vcc-supply = <&vdd_1v8_ls>;
								cam-type = "IR_L";
								orbbec_cam_num = <0>;
								nvidia,gmsl-ser-device = <&ser0_a>;
								nvidia,gmsl-dser-device = <&dser0>;
								pps-gpios = <&gpio_aon PPS_TRIGGER GPIO_ACTIVE_LOW>;
								ports {
									#address-cells = <1>;
									#size-cells = <0>;

									port@0 {
										reg = <0>;
										g2m0_2_out: endpoint {
											vc-id = <2>;
											port-index = <4>;
											bus-width = <4>;
											remote-endpoint = <&g2xx_csi_in2>;
										};
									};
								};
								mode0 {
									pixel_t = "grey_y8";
									num_lanes = "4";
									csi_pixel_bit_depth = "8";
									active_w = "1280";
									active_h = "720";
									tegra_sinterface = "serial_e";
									mclk_khz = "24000";
									pix_clk_hz = "750000000";
									serdes_pix_clk_hz = "750000000";
									discontinuous_clk = "no";
									dpcm_enable = "false";
									cil_settletime = "0";
									line_length = "1280";
									mclk_multiplier = "15.625";
									embedded_metadata_height = "1";
									vc_id = "2";
								};
								gmsl-link {
									src-csi-port = "a"; //a = depth + ir_l, b = rgb + ir_r
									dst-csi-port = "a";
									serdes-csi-link = "a";
									csi-mode = "1x4";
									st-vc = <2>;
									vc-id = <2>;
									num-lanes = <4>;
								};
							};
							/* RGB */
							g2m0_1: g2m1@67 {
								status = "okay";
								def-addr = <0x66>;
								reg = <0x67>;
								compatible = "orbbec,g2xx";
								use_sensor_mode_id = "true";
								vcc-supply = <&vdd_1v8_ls>;
								cam-type = "RGB";
								orbbec_cam_num = <0>;
								nvidia,gmsl-ser-device = <&ser0_a>;
								nvidia,gmsl-dser-device = <&dser0>;
								pps-gpios = <&gpio_aon PPS_TRIGGER GPIO_ACTIVE_LOW>;
								ports {
									#address-cells = <1>;
									#size-cells = <0>;

									port@0 {
										reg = <0>;
										g2m0_1_out: endpoint {
											vc-id = <1>;
											port-index = <4>;
											bus-width = <4>;
											remote-endpoint = <&g2xx_csi_in1>;
										};
									};
								};
								mode0 {
									pixel_t = "yuv_yvyu16";
									num_lanes = "4";
									csi_pixel_bit_depth = "16";
									active_w = "1280";
									active_h = "720";
									tegra_sinterface = "serial_e";
									mclk_khz = "24000";
									pix_clk_hz = "375000000";
									serdes_pix_clk_hz = "375000000";
									discontinuous_clk = "no";
									dpcm_enable = "false";
									cil_settletime = "0";
									line_length = "1280";
									mclk_multiplier = "15.625";
									embedded_metadata_height = "1"; 
									vc_id = "1";
								};
								gmsl-link {
									src-csi-port = "b"; //a = depth + ir_l, b = rgb + ir_r
									dst-csi-port = "a";
									serdes-csi-link = "a";
									csi-mode = "1x4";
									st-vc = <1>;
									vc-id = <1>;
									num-lanes = <4>;
								};
							};
							/* Depth */
							g2m0_0: g2m0@66 {
								status = "okay";
								def-addr = <0x66>;
								reg = <0x66>;
								compatible = "orbbec,g2xx";
								use_sensor_mode_id = "true";
								vcc-supply = <&vdd_1v8_ls>;
								cam-type = "Depth";
								orbbec_cam_num = <0>;
								nvidia,gmsl-ser-device = <&ser0_a>;
								nvidia,gmsl-dser-device = <&dser0>;
								pps-gpios = <&gpio_aon PPS_TRIGGER GPIO_ACTIVE_LOW>;
								ports {
									#address-cells = <1>;
									#size-cells = <0>;

									port@0 {
										reg = <0>;
										g2m0_0_out: endpoint {
											vc-id = <0>;
											port-index = <4>;
											bus-width = <4>;
											remote-endpoint = <&g2xx_csi_in0>;
										};
									};
								};
								mode0 {
									pixel_t = "yuv_yvyu16";
									num_lanes = "4";
									csi_pixel_bit_depth = "16";
									active_w = "1280";
									active_h = "720";
									tegra_sinterface = "serial_e";
									mclk_khz = "24000";
									pix_clk_hz = "375000000";
									serdes_pix_clk_hz = "375000000";
									discontinuous_clk = "no";
									dpcm_enable = "false";
									cil_settletime = "0";
									line_length = "1280";
									mclk_multiplier = "15.625";
									embedded_metadata_height = "1"; 
									vc_id = "0";
								};
								gmsl-link {
									/* a = depth + ir_l, b = rgb + ir_r */
									src-csi-port = "a";  		/**< Sensor to serializer CSI port connection. */
									dst-csi-port = "a";			/**< Deserializer to Jetson CSI port connection. */
									serdes-csi-link = "a";		/**< GMSL link between serializer and deserializer devices. */
									csi-mode = "1x4";			/**< Deserializer CSI mode. */
									st-vc = <0>;   				/**< Default sensor virtual channel. */
									vc-id = <0>;				/**< Destination virtual channel (user-defined). */
									num-lanes = <4>;			/**< Sensor's CSI lane configuration. */
								};
							};
							
							ser0_a: max9295_a@42 {
								status = "okay";
								compatible = "maxim,max9295";
								reg = <0x42>;
								ser-prim-device = <&ser_prim0>;
								maxim,gmsl-dser-device = <&dser0>;
							};

							ser0_b: max9295_b@60 {
								status = "okay";
								compatible = "maxim,max9295";
								reg = <0x60>;
								ser-prim-device = <&ser_prim0>;
								maxim,gmsl-dser-device = <&dser0>;
							};

							ser_prim0: max9295_prim@40 {
								status = "okay";
								reg = <0x40>;
								compatible = "maxim,max9295";
								is-prim-ser;
							};
								
							dser0: max9296@48 {
								status = "okay";
								reg = <0x48>;
								compatible = "maxim,max9296";
								csi-mode = "2x4";
								max-src = <2>;
								reset-gpios = <&gpio CAM3_PWDN GPIO_ACTIVE_HIGH>;
								poc-ctrl = <&gpio D457_POC GPIO_ACTIVE_HIGH>;
								fsync_mfp_index = <7>;
								pps_mfp_index = <9>;
							};
						};

						i2c@1 {
							status = "okay";
							reg = <1>; // line 4 of the I2C switch
							i2c-mux,deselect-on-exit;
							#address-cells = <1>;
							#size-cells = <0>;

							g2m3_3: g2m3@6D {
								status = "okay";
								def-addr = <0x66>;
								reg = <0x6D>;
								compatible = "orbbec,g2xx";
								use_sensor_mode_id = "true";
								vcc-supply = <&vdd_1v8_ls>;
								cam-type = "IR_R";
								orbbec_cam_num = <3>;
								nvidia,gmsl-ser-device = <&ser1_b>;
								nvidia,gmsl-dser-device = <&dser1>;
								pps-gpios = <&gpio_aon PPS_TRIGGER GPIO_ACTIVE_LOW>;
								ports {
									#address-cells = <1>;
									#size-cells = <0>;

									port@0 {
										reg = <0>;
										g2m3_3_out: endpoint {
											vc-id = <1>;
											port-index = <2>;
											bus-width = <4>;
											remote-endpoint = <&g2xx_csi_in15>;
										};
									};
								};
								mode0 {
									pixel_t = "grey_y8";
									num_lanes = "4";
									csi_pixel_bit_depth = "8";
									active_w = "1280";
									active_h = "720";
									tegra_sinterface = "serial_c";
									mclk_khz = "24000";
									pix_clk_hz = "750000000";
									serdes_pix_clk_hz = "750000000";
									discontinuous_clk = "no";
									dpcm_enable = "false";
									cil_settletime = "0";
									line_length = "1280";
									mclk_multiplier = "15.625";
									embedded_metadata_height = "1";
									vc_id = "1";
								};
								gmsl-link {
									src-csi-port = "b";
									dst-csi-port = "a";
									serdes-csi-link = "b";
									csi-mode = "1x4";
									st-vc = <3>;
									vc-id = <1>;
									num-lanes = <4>;
								};
							};
							g2m3_2: g2m2@6C {
								status = "okay";
								def-addr = <0x66>;
								reg = <0x6C>;
								compatible = "orbbec,g2xx";
								use_sensor_mode_id = "true";
								vcc-supply = <&vdd_1v8_ls>;
								cam-type = "IR_L";
								orbbec_cam_num = <3>;
								nvidia,gmsl-ser-device = <&ser1_b>;
								nvidia,gmsl-dser-device = <&dser1>;
								pps-gpios = <&gpio_aon PPS_TRIGGER GPIO_ACTIVE_LOW>;
								ports {
									#address-cells = <1>;
									#size-cells = <0>;

									port@0 {
										reg = <0>;
										g2m3_2_out: endpoint {
											vc-id = <0>;
											port-index = <2>;
											bus-width = <4>;
											remote-endpoint = <&g2xx_csi_in14>;
										};
									};
								};
								mode0 {
									pixel_t = "grey_y8";
									num_lanes = "4";
									csi_pixel_bit_depth = "8";
									active_w = "1280";
									active_h = "720";
									tegra_sinterface = "serial_c";
									mclk_khz = "24000";
									pix_clk_hz = "750000000";
									serdes_pix_clk_hz = "750000000";
									discontinuous_clk = "no";
									dpcm_enable = "false";
									cil_settletime = "0";
									line_length = "1280";
									mclk_multiplier = "15.625";
									embedded_metadata_height = "1";
									vc_id = "0";
								};
								gmsl-link {
									src-csi-port = "a";
									dst-csi-port = "a";
									serdes-csi-link = "b";
									csi-mode = "1x4";
									st-vc = <2>;
									vc-id = <0>;
									num-lanes = <4>;
								};
							};
							g2m3_1: g2m1@6B {
								status = "okay";
								def-addr = <0x66>;
								reg = <0x6B>;
								compatible = "orbbec,g2xx";
								use_sensor_mode_id = "true";
								vcc-supply = <&vdd_1v8_ls>;
								cam-type = "RGB";
								orbbec_cam_num = <3>;
								nvidia,gmsl-ser-device = <&ser1_b>;
								nvidia,gmsl-dser-device = <&dser1>;
								pps-gpios = <&gpio_aon PPS_TRIGGER GPIO_ACTIVE_LOW>;
								ports {
									#address-cells = <1>;
									#size-cells = <0>;

									port@0 {
										reg = <0>;
										g2m3_1_out: endpoint {
											vc-id = <3>;
											port-index = <2>;
											bus-width = <4>;
											remote-endpoint = <&g2xx_csi_in13>;
										};
									};
								};
								mode0 {
									pixel_t = "yuv_yvyu16";
									num_lanes = "4";
									csi_pixel_bit_depth = "16";
									active_w = "1280";
									active_h = "720";
									tegra_sinterface = "serial_c";
									mclk_khz = "24000";
									pix_clk_hz = "375000000";
									serdes_pix_clk_hz = "375000000";
									discontinuous_clk = "no";
									dpcm_enable = "false";
									cil_settletime = "0";
									line_length = "1280";
									mclk_multiplier = "15.625";
									embedded_metadata_height = "1"; 
									vc_id = "3";
								};
								gmsl-link {
									src-csi-port = "b";
									dst-csi-port = "a";
									serdes-csi-link = "b";
									csi-mode = "1x4";
									st-vc = <1>;
									vc-id = <3>;
									num-lanes = <4>;
								};
							};
							g2m3_0: g2m0@6A {
								status = "okay";
								def-addr = <0x66>;
								reg = <0x6A>;
								compatible = "orbbec,g2xx";
								use_sensor_mode_id = "true";
								vcc-supply = <&vdd_1v8_ls>;
								cam-type = "Depth";
								orbbec_cam_num = <3>;
								nvidia,gmsl-ser-device = <&ser1_b>;
								nvidia,gmsl-dser-device = <&dser1>;
								pps-gpios = <&gpio_aon PPS_TRIGGER GPIO_ACTIVE_LOW>;
								ports {
									#address-cells = <1>;
									#size-cells = <0>;

									port@0 {
										reg = <0>;
										g2m3_0_out: endpoint {
											vc-id = <2>;
											port-index = <2>;
											bus-width = <4>;
											remote-endpoint = <&g2xx_csi_in12>;
										};
									};
								};
								mode0 {
									pixel_t = "yuv_yvyu16";
									num_lanes = "4";
									csi_pixel_bit_depth = "16";
									active_w = "1280";
									active_h = "720";
									tegra_sinterface = "serial_c";
									mclk_khz = "24000";
									pix_clk_hz = "375000000";
									serdes_pix_clk_hz = "375000000";
									discontinuous_clk = "no";
									dpcm_enable = "false";
									cil_settletime = "0";
									line_length = "1280";
									mclk_multiplier = "15.625";
									embedded_metadata_height = "1"; 
									vc_id = "2";
								};
								gmsl-link {
									src-csi-port = "a";
									dst-csi-port = "a";
									serdes-csi-link = "b";
									csi-mode = "1x4";
									st-vc = <0>;
									vc-id = <2>;
									num-lanes = <4>;
								};
							};
							
							g2m2_3: g2m3@69 {
								status = "okay";
								def-addr = <0x66>;
								reg = <0x69>;
								compatible = "orbbec,g2xx";
								use_sensor_mode_id = "true";
								vcc-supply = <&vdd_1v8_ls>;
								cam-type = "IR_R";
								orbbec_cam_num = <2>;
								nvidia,gmsl-ser-device = <&ser1_a>;
								nvidia,gmsl-dser-device = <&dser1>;
								pps-gpios = <&gpio_aon PPS_TRIGGER GPIO_ACTIVE_LOW>;
								ports {
									#address-cells = <1>;
									#size-cells = <0>;

									port@0 {
										reg = <0>;
										g2m2_3_out: endpoint {
											vc-id = <3>;
											port-index = <2>;
											bus-width = <4>;
											remote-endpoint = <&g2xx_csi_in11>;
										};
									};
								};
								mode0 {
									pixel_t = "grey_y8";
									num_lanes = "4";
									csi_pixel_bit_depth = "8";
									active_w = "1280";
									active_h = "720";
									tegra_sinterface = "serial_c";
									mclk_khz = "24000";
									pix_clk_hz = "750000000";
									serdes_pix_clk_hz = "750000000";
									discontinuous_clk = "no";
									dpcm_enable = "false";
									cil_settletime = "0";
									line_length = "1280";
									mclk_multiplier = "15.625";
									embedded_metadata_height = "1";
									vc_id = "3";
								};
								gmsl-link {
									src-csi-port = "b";
									dst-csi-port = "a";
									serdes-csi-link = "a";
									csi-mode = "1x4";
									st-vc = <3>;
									vc-id = <3>;
									num-lanes = <4>;
								};
							};
							g2m2_2: g2m2@68 {
								status = "okay";
								def-addr = <0x66>;
								reg = <0x68>;
								compatible = "orbbec,g2xx";
								use_sensor_mode_id = "true";
								vcc-supply = <&vdd_1v8_ls>;
								cam-type = "IR_L";
								orbbec_cam_num = <2>;
								nvidia,gmsl-ser-device = <&ser1_a>;
								nvidia,gmsl-dser-device = <&dser1>;
								pps-gpios = <&gpio_aon PPS_TRIGGER GPIO_ACTIVE_LOW>;
								ports {
									#address-cells = <1>;
									#size-cells = <0>;

									port@0 {
										reg = <0>;
										g2m2_2_out: endpoint {
											vc-id = <2>;
											port-index = <2>;
											bus-width = <4>;
											remote-endpoint = <&g2xx_csi_in10>;
										};
									};
								};
								mode0 {
									pixel_t = "grey_y8";
									num_lanes = "4";
									csi_pixel_bit_depth = "8";
									active_w = "1280";
									active_h = "720";
									tegra_sinterface = "serial_c";
									mclk_khz = "24000";
									pix_clk_hz = "750000000";
									serdes_pix_clk_hz = "750000000";
									discontinuous_clk = "no";
									dpcm_enable = "false";
									cil_settletime = "0";
									line_length = "1280";
									mclk_multiplier = "15.625";
									embedded_metadata_height = "1";
									vc_id = "2";
								};
								gmsl-link {
									src-csi-port = "a";
									dst-csi-port = "a";
									serdes-csi-link = "a";
									csi-mode = "1x4";
									st-vc = <2>;
									vc-id = <2>;
									num-lanes = <4>;
								};
							};
							g2m2_1: g2m1@67 {
								status = "okay";
								def-addr = <0x66>;
								reg = <0x67>;
								compatible = "orbbec,g2xx";
								use_sensor_mode_id = "true";
								vcc-supply = <&vdd_1v8_ls>;
								cam-type = "RGB";
								orbbec_cam_num = <2>;
								nvidia,gmsl-ser-device = <&ser1_a>;
								nvidia,gmsl-dser-device = <&dser1>;
								pps-gpios = <&gpio_aon PPS_TRIGGER GPIO_ACTIVE_LOW>;
								ports {
									#address-cells = <1>;
									#size-cells = <0>;

									port@0 {
										reg = <0>;
										g2m2_1_out: endpoint {
											vc-id = <1>;
											port-index = <2>;
											bus-width = <4>;
											remote-endpoint = <&g2xx_csi_in9>;
										};
									};
								};
								mode0 {
									pixel_t = "yuv_yvyu16";
									num_lanes = "4";
									csi_pixel_bit_depth = "16";
									active_w = "1280";
									active_h = "720";
									tegra_sinterface = "serial_c";
									mclk_khz = "24000";
									pix_clk_hz = "375000000";
									serdes_pix_clk_hz = "375000000";
									discontinuous_clk = "no";
									dpcm_enable = "false";
									cil_settletime = "0";
									line_length = "1280";
									mclk_multiplier = "15.625";
									embedded_metadata_height = "1";
									vc_id = "1";
								};
								gmsl-link {
									src-csi-port = "b";
									dst-csi-port = "a";
									serdes-csi-link = "a";
									csi-mode = "1x4";
									st-vc = <1>;
									vc-id = <1>;
									num-lanes = <4>;
								};
							};
							g2m2_0: g2m0@66 {
								status = "okay";
								def-addr = <0x66>;
								reg = <0x66>;
								compatible = "orbbec,g2xx";
								use_sensor_mode_id = "true";
								vcc-supply = <&vdd_1v8_ls>;
								cam-type = "Depth";
								orbbec_cam_num = <2>;
								nvidia,gmsl-ser-device = <&ser1_a>;
								nvidia,gmsl-dser-device = <&dser1>;
								pps-gpios = <&gpio_aon PPS_TRIGGER GPIO_ACTIVE_LOW>;
								ports {
									#address-cells = <1>;
									#size-cells = <0>;

									port@0 {
										reg = <0>;
										g2m2_0_out: endpoint {
											vc-id = <0>;
											port-index = <2>;
											bus-width = <4>;
											remote-endpoint = <&g2xx_csi_in8>;
										};
									};
								};
								mode0 {
									pixel_t = "yuv_yvyu16";
									num_lanes = "4";
									csi_pixel_bit_depth = "16";
									active_w = "1280";
									active_h = "720";
									tegra_sinterface = "serial_c";
									mclk_khz = "24000";
									pix_clk_hz = "375000000";
									serdes_pix_clk_hz = "375000000";
									discontinuous_clk = "no";
									dpcm_enable = "false";
									cil_settletime = "0";
									line_length = "1280";
									mclk_multiplier = "15.625";
									embedded_metadata_height = "1";
									vc_id = "0";
								};
								gmsl-link {
									src-csi-port = "a";  		/**< Sensor to serializer CSI port connection. */
									dst-csi-port = "a";			/**< Deserializer to Jetson CSI port connection. */
									serdes-csi-link = "a";		/**< GMSL link between serializer and deserializer devices. */
									csi-mode = "1x4";			/**< Deserializer CSI mode. */
									st-vc = <0>;   				/**< Default sensor virtual channel. */
									vc-id = <0>;				/**< Destination virtual channel (user-defined). */
									num-lanes = <4>;			/**< Sensor's CSI lane configuration. */
								};
							};

							ser1_a: max9295_a@42 {
								status = "okay";
								compatible = "maxim,max9295";
								reg = <0x42>;
								ser-prim-device = <&ser_prim1>;
								maxim,gmsl-dser-device = <&dser1>;
							};

							ser1_b: max9295_b@60 {
								status = "okay";
								compatible = "maxim,max9295";
								reg = <0x60>;
								ser-prim-device = <&ser_prim1>;
								maxim,gmsl-dser-device = <&dser1>;
							};

							ser_prim1: max9295_prim@40 {
								status = "okay";
								reg = <0x40>;
								compatible = "maxim,max9295";
								is-prim-ser;
							};

							dser1: max9296@48 {
								status = "okay";
								reg = <0x48>;
								compatible = "maxim,max9296";
								csi-mode = "2x4";
								max-src = <2>;
								reset-gpios = <&gpio CAM2_PWDN GPIO_ACTIVE_HIGH>;
								poc-ctrl = <&gpio D457_POC GPIO_ACTIVE_HIGH>;
								fsync_mfp_index = <7>;
								pps_mfp_index = <9>;
							};
						};

						i2c@2 {
                            status = "okay";
							reg = <2>; // line 4 of the I2C switch
							i2c-mux,deselect-on-exit;
							#address-cells = <1>;
							#size-cells = <0>;

			            	fzcam_b@2b {
			            		compatible = "nvidia,fzcam";
			            		reg = <0x2b>;

			            		devnode = "video1";
			            		sensor_model ="fzcam";

			            		/* Define any required hw resources needed by driver */
			            		/* ie. clocks, io pins, power sources */
			            		clocks = <&bpmp TEGRA234_CLK_EXTPERIPH1>,
			            				<&bpmp TEGRA234_CLK_EXTPERIPH1>;
			            		clock-names = "extperiph1", "pllp_grtba";
			            		mclk = "extperiph1";
			            		channel = <0>;

			            		mode0 {
			            			mclk_khz = "37125";
			            			num_lanes = "4";
			            			tegra_sinterface = "serial_a";
			            			vc_id = "1";

			            			discontinuous_clk = "no";
			            			dpcm_enable = "false";
			            			cil_settletime = "0";

			            			csi_pixel_bit_depth = "16";
			            			mode_type = "yuv";
			            			pixel_phase = "uyvy";

			            			active_w = "1920";
			            			active_h = "1536";
			            			readout_orientation = "0";
			            			line_length = "2200";
			            			inherent_gain = "1";

			            			pix_clk_hz = "74250000";
			            			serdes_pix_clk_hz = "375000000";

			            			gain_factor = "10";
			            			min_gain_val = "1"; /* 0dB */
			            			max_gain_val = "480"; /* 48dB */
			            			step_gain_val = "3"; /* 0.3 */
			            			default_gain = "1";
			            			framerate_factor = "1000000";
			            			min_framerate = "30000000"; /* 1.5 */
			            			max_framerate = "30000000"; /* 30 */
			            			step_framerate = "1";
			            			default_framerate= "30000000";
			            			exposure_factor = "1000000";
			            			min_exp_time = "30"; /* us */
			            			max_exp_time = "660000"; /* us */
			            			step_exp_time = "1";
			            			default_exp_time = "33334";/* us */
			            			embedded_metadata_height = "0";
			            		};

			            		ports {
			            			#address-cells = <1>;
			            			#size-cells = <0>;
			            			port@0 {
			            				reg = <0>;
			            				fzcam_fzcam_out1: endpoint {
			            					vc-id = <1>;
			            					port-index = <0>;
			            					bus-width = <4>;
			            					remote-endpoint = <&fzcam_csi_in1>;
			            				};
			            			};
			            		};
                            };

			            	fzcam_a@2a {
			            		compatible = "nvidia,fzcam";
			            		reg = <0x2a>;

			            		devnode = "video0";
			            		sensor_model ="fzcam";

			            		clocks = <&bpmp TEGRA234_CLK_EXTPERIPH1>,
			            				<&bpmp TEGRA234_CLK_EXTPERIPH1>;
			            		clock-names = "extperiph1", "pllp_grtba";
			            		mclk = "extperiph1";
			            		channel = <0>;

			            		mode0 {
			            			mclk_khz = "37125";
			            			num_lanes = "4";
			            			tegra_sinterface = "serial_a";
			            			vc_id = "0";

			            			discontinuous_clk = "no";
			            			dpcm_enable = "false";
			            			cil_settletime = "0";

			            			csi_pixel_bit_depth = "16";
			            			mode_type = "yuv";
			            			pixel_phase = "uyvy";

			            			active_w = "1920";
			            			active_h = "1536";
			            			readout_orientation = "0";
			            			line_length = "2200";
			            			inherent_gain = "1";

			            			pix_clk_hz = "74250000";
			            			serdes_pix_clk_hz = "375000000";

			            			gain_factor = "10";
			            			min_gain_val = "1"; /* 0dB */
			            			max_gain_val = "480"; /* 48dB */
			            			step_gain_val = "3"; /* 0.3 */
			            			default_gain = "1";
			            			framerate_factor = "1000000";
			            			min_framerate = "30000000"; /* 1.5 */
			            			max_framerate = "30000000"; /* 30 */
			            			step_framerate = "1";
			            			default_framerate= "30000000";

			            			exposure_factor = "1000000";
			            			min_exp_time = "30"; /* us */
			            			max_exp_time = "660000"; /* us */
			            			step_exp_time = "1";
			            			default_exp_time = "33334";/* us */
			            			embedded_metadata_height = "0";
			            		};

			            		ports {
			            			#address-cells = <1>;
			            			#size-cells = <0>;
			            			port@0 {
			            				reg = <0>;
			            				fzcam_fzcam_out0: endpoint {
			            					vc-id = <0>;
			            					port-index = <0>;
			            					bus-width = <4>;
			            					remote-endpoint = <&fzcam_csi_in0>;
			            					};
			            				};
			            			};
			            	};

                            serdes@48 {
			            		compatible = "nvidia,serdes";
			            		reg = <0x48>;
			            		pwdn-gpios = <&gpio CAM1_PWDN GPIO_ACTIVE_HIGH>;
								poc-ctrl = <&gpio ISX031_POC GPIO_ACTIVE_HIGH>;
			            		channel = <0>;
			            	};

                        };
						
						i2c@3 {   //max96712
							status = "okay";
							reg = <3>; // line 4 of the I2C switch
							i2c-mux,deselect-on-exit;
							#address-cells = <1>;
							#size-cells = <0>;
		
			            	fzcam_d@2d {
			            		compatible = "nvidia,fzcama";
			            		reg = <0x2d>;

			            		devnode = "video5";	
			            		sensor_model ="fzcama";

			            		/* Define any required hw resources needed by driver */
			            		/* ie. clocks, io pins, power sources */
			            		clocks = <&bpmp TEGRA234_CLK_EXTPERIPH1>,
			            				<&bpmp TEGRA234_CLK_EXTPERIPH1>;
			            		clock-names = "extperiph1", "pllp_grtba";
			            		mclk = "extperiph1";
			            		channel = <1>;			

			            		mode0 {
			            			mclk_khz = "37125";
			            			num_lanes = "4";
			            			tegra_sinterface = "serial_g";
			            			vc_id = "3";

			            			discontinuous_clk = "no";
			            			dpcm_enable = "false";
			            			cil_settletime = "0";

			            			csi_pixel_bit_depth = "16";
			            			mode_type = "yuv";
			            			pixel_phase = "uyvy";

			            			active_w = "1920";
			            			active_h = "1536";
			            			readout_orientation = "0";
			            			line_length = "2200";
			            			inherent_gain = "1";

			            			pix_clk_hz = "74250000";
			            			serdes_pix_clk_hz = "375000000";

			            			gain_factor = "10";
			            			min_gain_val = "1"; /* 0dB */
			            			max_gain_val = "480"; /* 48dB */
			            			step_gain_val = "3"; /* 0.3 */
			            			default_gain = "1";
			            			framerate_factor = "1000000";
			            			min_framerate = "30000000"; /* 1.5 */
			            			max_framerate = "30000000"; /* 30 */
			            			step_framerate = "1";
			            			default_framerate= "30000000";

			            			exposure_factor = "1000000";
			            			min_exp_time = "30"; /* us */
			            			max_exp_time = "660000"; /* us */
			            			step_exp_time = "1";
			            			default_exp_time = "33334";/* us */

			            			embedded_metadata_height = "0";
			            		};

			            		ports {
			            			#address-cells = <1>;
			            			#size-cells = <0>;
			            			port@0 {
			            				reg = <0>;
			            				fzcam_fzcam_out5: endpoint {
			            					vc-id = <3>;
			            					port-index = <5>;
			            					bus-width = <4>;
			            					remote-endpoint = <&fzcam_csi_in5>;
			            				};
			            			};
			            		};
			            	};

                            fzcam_c@2c {
			            		compatible = "nvidia,fzcama";
			            		reg = <0x2c>;

			            		devnode = "video4";
			            		sensor_model ="fzcama";

			            		/* Define any required hw resources needed by driver */
			            		/* ie. clocks, io pins, power sources */
			            		clocks = <&bpmp TEGRA234_CLK_EXTPERIPH1>,
			            				<&bpmp TEGRA234_CLK_EXTPERIPH1>;
			            		clock-names = "extperiph1", "pllp_grtba";
			            		mclk = "extperiph1";
			            		channel = <1>;

			            		mode0 {
			            			mclk_khz = "37125";
			            			num_lanes = "4";
			            			tegra_sinterface = "serial_g";
			            			vc_id = "2";

			            			discontinuous_clk = "no";
			            			dpcm_enable = "false";
			            			cil_settletime = "0";

			            			csi_pixel_bit_depth = "16";
			            			mode_type = "yuv";
			            			pixel_phase = "uyvy";

			            			active_w = "1920";
			            			active_h = "1536";
			            			readout_orientation = "0";
			            			line_length = "2200";
			            			inherent_gain = "1";

			            			pix_clk_hz = "74250000";
			            			serdes_pix_clk_hz = "375000000";

			            			gain_factor = "10";
			            			min_gain_val = "1"; /* 0dB */
			            			max_gain_val = "480"; /* 48dB */
			            			step_gain_val = "3"; /* 0.3 */
			            			default_gain = "1";
			            			framerate_factor = "1000000";
			            			min_framerate = "30000000"; /* 1.5 */
			            			max_framerate = "30000000"; /* 30 */
			            			step_framerate = "1";
			            			default_framerate= "30000000";

			            			exposure_factor = "1000000";
			            			min_exp_time = "30"; /* us */
			            			max_exp_time = "660000"; /* us */
			            			step_exp_time = "1";
			            			default_exp_time = "33334";/* us */
			            			embedded_metadata_height = "0";
			            		};

			            		ports {
			            			#address-cells = <1>;
			            			#size-cells = <0>;
			            			port@0 {
			            				reg = <0>;
			            				fzcam_fzcam_out4: endpoint {
			            					vc-id = <2>;
			            					port-index = <5>;
			            					bus-width = <4>;
			            					remote-endpoint = <&fzcam_csi_in4>;
			            					};
			            				};
			            			};
			            	};

                            fzcam_b@2b {
			            		compatible = "nvidia,fzcama";
			            		reg = <0x2b>;

			            		devnode = "video3";
			            		sensor_model ="fzcama";

			            		/* Define any required hw resources needed by driver */
			            		/* ie. clocks, io pins, power sources */
			            		clocks = <&bpmp TEGRA234_CLK_EXTPERIPH1>,
			            				<&bpmp TEGRA234_CLK_EXTPERIPH1>;
			            		clock-names = "extperiph1", "pllp_grtba";
			            		mclk = "extperiph1";
			            		channel = <1>;

			            		mode0 {
			            			mclk_khz = "37125";
			            			num_lanes = "4";
			            			tegra_sinterface = "serial_g";
			            			vc_id = "1";

			            			discontinuous_clk = "no";
			            			dpcm_enable = "false";
			            			cil_settletime = "0";

			            			csi_pixel_bit_depth = "16";
			            			mode_type = "yuv";
			            			pixel_phase = "uyvy";

			            			active_w = "1920";
			            			active_h = "1536";
			            			readout_orientation = "0";
			            			line_length = "2200";
			            			inherent_gain = "1";

			            			pix_clk_hz = "74250000";
			            			serdes_pix_clk_hz = "375000000";

			            			gain_factor = "10";
			            			min_gain_val = "1"; /* 0dB */
			            			max_gain_val = "480"; /* 48dB */
			            			step_gain_val = "3"; /* 0.3 */
			            			default_gain = "1";
			            			framerate_factor = "1000000";
			            			min_framerate = "30000000"; /* 1.5 */
			            			max_framerate = "30000000"; /* 30 */
			            			step_framerate = "1";
			            			default_framerate= "30000000";

			            			exposure_factor = "1000000";
			            			min_exp_time = "30"; /* us */
			            			max_exp_time = "660000"; /* us */
			            			step_exp_time = "1";
			            			default_exp_time = "33334";/* us */
			            			embedded_metadata_height = "0";
			            		};
			            		ports {
			            			#address-cells = <1>;
			            			#size-cells = <0>;
			            			port@0 {
			            				reg = <0>;
			            				fzcam_fzcam_out3: endpoint {
			            					vc-id = <1>;
			            					port-index = <5>;
			            					bus-width = <4>;
			            					remote-endpoint = <&fzcam_csi_in3>;
			            				};
			            			};
			            		};
			            	};	

                            fzcam_a@2a {
			            		compatible = "nvidia,fzcama";
			            		reg = <0x2a>;

			            		devnode = "video2";
			            		sensor_model ="fzcama";

			            		/* Define any required hw resources needed by driver */
			            		/* ie. clocks, io pins, power sources */
			            		clocks = <&bpmp TEGRA234_CLK_EXTPERIPH1>,
			            				<&bpmp TEGRA234_CLK_EXTPERIPH1>;
			            		clock-names = "extperiph1", "pllp_grtba";
			            		mclk = "extperiph1";
			            		channel = <1>;

			            		mode0 {
			            			mclk_khz = "37125";
			            			num_lanes = "4";
			            			tegra_sinterface = "serial_g";
			            			vc_id = "0";

			            			discontinuous_clk = "no";
			            			dpcm_enable = "false";
			            			cil_settletime = "0";

			            			csi_pixel_bit_depth = "16";
			            			mode_type = "yuv";
			            			pixel_phase = "uyvy";

			            			active_w = "1920";
			            			active_h = "1536";
			            			readout_orientation = "0";
			            			line_length = "2200";
			            			inherent_gain = "1";

			            			pix_clk_hz = "74250000";
			            			serdes_pix_clk_hz = "375000000";

			            			gain_factor = "10";
			            			min_gain_val = "1"; /* 0dB */
			            			max_gain_val = "480"; /* 48dB */
			            			step_gain_val = "3"; /* 0.3 */
			            			default_gain = "1";
			            			framerate_factor = "1000000";
			            			min_framerate = "30000000"; /* 1.5 */
			            			max_framerate = "30000000"; /* 30 */
			            			step_framerate = "1";
			            			default_framerate= "30000000";

			            			exposure_factor = "1000000";
			            			min_exp_time = "30"; /* us */
			            			max_exp_time = "660000"; /* us */
			            			step_exp_time = "1";
			            			default_exp_time = "33334";/* us */

			            			embedded_metadata_height = "0";
			            		};

			            		ports {
			            			#address-cells = <1>;
			            			#size-cells = <0>;
			            			port@0 {
			            				reg = <0>;
			            				fzcam_fzcam_out2: endpoint {
			            					vc-id = <0>;
			            					port-index = <5>;
			            					bus-width = <4>;
			            					remote-endpoint = <&fzcam_csi_in2>;
			            				};
			            			};
			            		};
			            	};

                            serdes@29 {
			            		compatible = "nvidia,serdesa";
			            		reg = <0x29>;
			            		pwdn-gpios = <&gpio CAM4_PWDN GPIO_ACTIVE_HIGH>;
								poc-ctrl = <&gpio ISX031_POC GPIO_ACTIVE_HIGH>;
			            		channel = <1>;
			            	};				
						};
					};
				};
			};
		};
	};
};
